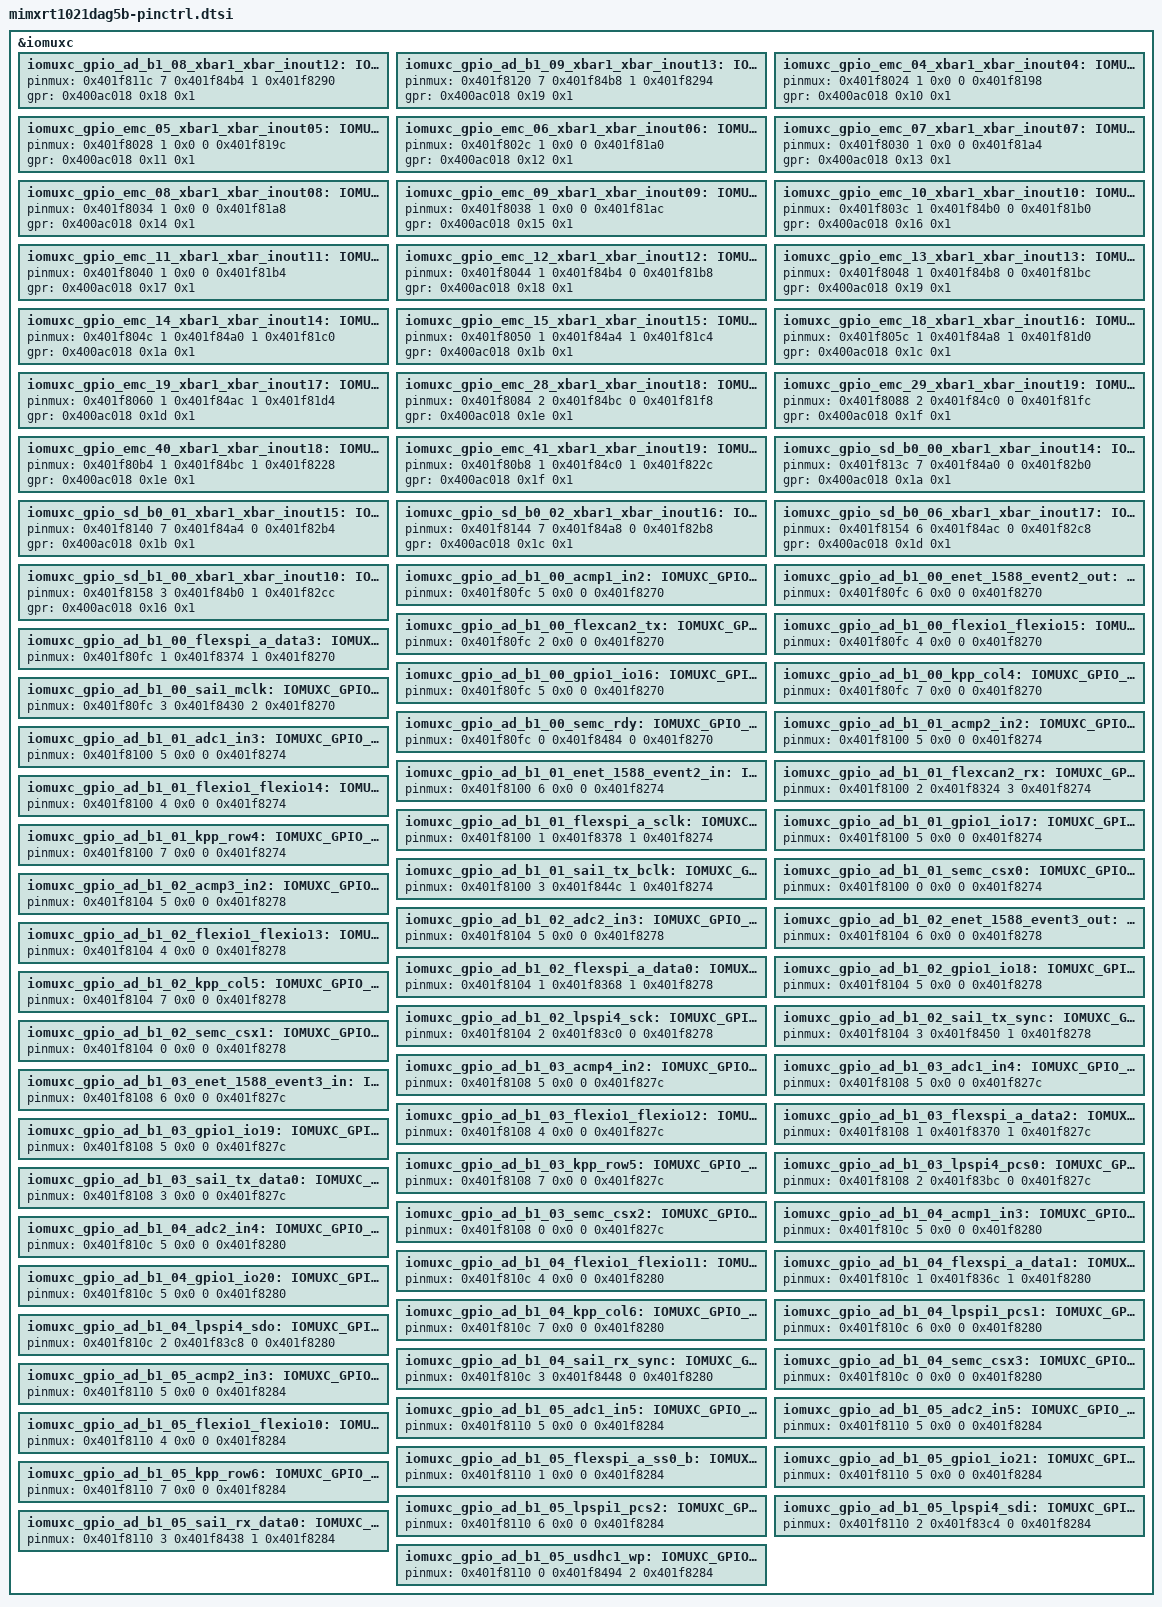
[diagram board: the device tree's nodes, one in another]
/*
 * Copyright 2024, NXP
 * SPDX-License-Identifier: Apache-2.0
 *
 * Note: File generated by gen_soc_headers.py
 * from configuration data for MIMXRT1021DAG5B
 */

/*
 * Delta-deduplicated by dedup_pinctrl.py:
 * based on mimxrt1024dag5a-pinctrl.dtsi with this part's differences applied
 * below (3 removed, 25 changed,
 * 60 added). Regenerate with dedup_pinctrl.py;
 * do not edit by hand.
 * target-hash: 459db1daa55398a1
 */

#include "mimxrt1024dag5a-pinctrl.dtsi"

/delete-node/ &iomuxc_gpio_ad_b0_13_arm_trace1;
/delete-node/ &iomuxc_gpio_ad_b0_14_arm_trace2;
/delete-node/ &iomuxc_gpio_ad_b0_15_arm_trace3;
/delete-node/ &iomuxc_gpio_ad_b1_08_xbar1_xbar_inout12;
/delete-node/ &iomuxc_gpio_ad_b1_09_xbar1_xbar_inout13;
/delete-node/ &iomuxc_gpio_emc_04_xbar1_xbar_inout04;
/delete-node/ &iomuxc_gpio_emc_05_xbar1_xbar_inout05;
/delete-node/ &iomuxc_gpio_emc_06_xbar1_xbar_inout06;
/delete-node/ &iomuxc_gpio_emc_07_xbar1_xbar_inout07;
/delete-node/ &iomuxc_gpio_emc_08_xbar1_xbar_inout08;
/delete-node/ &iomuxc_gpio_emc_09_xbar1_xbar_inout09;
/delete-node/ &iomuxc_gpio_emc_10_xbar1_xbar_inout10;
/delete-node/ &iomuxc_gpio_emc_11_xbar1_xbar_inout11;
/delete-node/ &iomuxc_gpio_emc_12_xbar1_xbar_inout12;
/delete-node/ &iomuxc_gpio_emc_13_xbar1_xbar_inout13;
/delete-node/ &iomuxc_gpio_emc_14_xbar1_xbar_inout14;
/delete-node/ &iomuxc_gpio_emc_15_xbar1_xbar_inout15;
/delete-node/ &iomuxc_gpio_emc_18_xbar1_xbar_inout16;
/delete-node/ &iomuxc_gpio_emc_19_xbar1_xbar_inout17;
/delete-node/ &iomuxc_gpio_emc_28_xbar1_xbar_inout18;
/delete-node/ &iomuxc_gpio_emc_29_xbar1_xbar_inout19;
/delete-node/ &iomuxc_gpio_emc_40_xbar1_xbar_inout18;
/delete-node/ &iomuxc_gpio_emc_41_xbar1_xbar_inout19;
/delete-node/ &iomuxc_gpio_sd_b0_00_xbar1_xbar_inout14;
/delete-node/ &iomuxc_gpio_sd_b0_01_xbar1_xbar_inout15;
/delete-node/ &iomuxc_gpio_sd_b0_02_xbar1_xbar_inout16;
/delete-node/ &iomuxc_gpio_sd_b0_06_xbar1_xbar_inout17;
/delete-node/ &iomuxc_gpio_sd_b1_00_xbar1_xbar_inout10;

&iomuxc {
	/omit-if-no-ref/ iomuxc_gpio_ad_b1_08_xbar1_xbar_inout12: IOMUXC_GPIO_AD_B1_08_XBAR1_XBAR_INOUT12 {
		pinmux = <0x401f811c 7 0x401f84b4 1 0x401f8290>;
		gpr = <0x400ac018 0x18 0x1>;
	};
	/omit-if-no-ref/ iomuxc_gpio_ad_b1_09_xbar1_xbar_inout13: IOMUXC_GPIO_AD_B1_09_XBAR1_XBAR_INOUT13 {
		pinmux = <0x401f8120 7 0x401f84b8 1 0x401f8294>;
		gpr = <0x400ac018 0x19 0x1>;
	};
	/omit-if-no-ref/ iomuxc_gpio_emc_04_xbar1_xbar_inout04: IOMUXC_GPIO_EMC_04_XBAR1_XBAR_INOUT04 {
		pinmux = <0x401f8024 1 0x0 0 0x401f8198>;
		gpr = <0x400ac018 0x10 0x1>;
	};
	/omit-if-no-ref/ iomuxc_gpio_emc_05_xbar1_xbar_inout05: IOMUXC_GPIO_EMC_05_XBAR1_XBAR_INOUT05 {
		pinmux = <0x401f8028 1 0x0 0 0x401f819c>;
		gpr = <0x400ac018 0x11 0x1>;
	};
	/omit-if-no-ref/ iomuxc_gpio_emc_06_xbar1_xbar_inout06: IOMUXC_GPIO_EMC_06_XBAR1_XBAR_INOUT06 {
		pinmux = <0x401f802c 1 0x0 0 0x401f81a0>;
		gpr = <0x400ac018 0x12 0x1>;
	};
	/omit-if-no-ref/ iomuxc_gpio_emc_07_xbar1_xbar_inout07: IOMUXC_GPIO_EMC_07_XBAR1_XBAR_INOUT07 {
		pinmux = <0x401f8030 1 0x0 0 0x401f81a4>;
		gpr = <0x400ac018 0x13 0x1>;
	};
	/omit-if-no-ref/ iomuxc_gpio_emc_08_xbar1_xbar_inout08: IOMUXC_GPIO_EMC_08_XBAR1_XBAR_INOUT08 {
		pinmux = <0x401f8034 1 0x0 0 0x401f81a8>;
		gpr = <0x400ac018 0x14 0x1>;
	};
	/omit-if-no-ref/ iomuxc_gpio_emc_09_xbar1_xbar_inout09: IOMUXC_GPIO_EMC_09_XBAR1_XBAR_INOUT09 {
		pinmux = <0x401f8038 1 0x0 0 0x401f81ac>;
		gpr = <0x400ac018 0x15 0x1>;
	};
	/omit-if-no-ref/ iomuxc_gpio_emc_10_xbar1_xbar_inout10: IOMUXC_GPIO_EMC_10_XBAR1_XBAR_INOUT10 {
		pinmux = <0x401f803c 1 0x401f84b0 0 0x401f81b0>;
		gpr = <0x400ac018 0x16 0x1>;
	};
	/omit-if-no-ref/ iomuxc_gpio_emc_11_xbar1_xbar_inout11: IOMUXC_GPIO_EMC_11_XBAR1_XBAR_INOUT11 {
		pinmux = <0x401f8040 1 0x0 0 0x401f81b4>;
		gpr = <0x400ac018 0x17 0x1>;
	};
	/omit-if-no-ref/ iomuxc_gpio_emc_12_xbar1_xbar_inout12: IOMUXC_GPIO_EMC_12_XBAR1_XBAR_INOUT12 {
		pinmux = <0x401f8044 1 0x401f84b4 0 0x401f81b8>;
		gpr = <0x400ac018 0x18 0x1>;
	};
	/omit-if-no-ref/ iomuxc_gpio_emc_13_xbar1_xbar_inout13: IOMUXC_GPIO_EMC_13_XBAR1_XBAR_INOUT13 {
		pinmux = <0x401f8048 1 0x401f84b8 0 0x401f81bc>;
		gpr = <0x400ac018 0x19 0x1>;
	};
	/omit-if-no-ref/ iomuxc_gpio_emc_14_xbar1_xbar_inout14: IOMUXC_GPIO_EMC_14_XBAR1_XBAR_INOUT14 {
		pinmux = <0x401f804c 1 0x401f84a0 1 0x401f81c0>;
		gpr = <0x400ac018 0x1a 0x1>;
	};
	/omit-if-no-ref/ iomuxc_gpio_emc_15_xbar1_xbar_inout15: IOMUXC_GPIO_EMC_15_XBAR1_XBAR_INOUT15 {
		pinmux = <0x401f8050 1 0x401f84a4 1 0x401f81c4>;
		gpr = <0x400ac018 0x1b 0x1>;
	};
	/omit-if-no-ref/ iomuxc_gpio_emc_18_xbar1_xbar_inout16: IOMUXC_GPIO_EMC_18_XBAR1_XBAR_INOUT16 {
		pinmux = <0x401f805c 1 0x401f84a8 1 0x401f81d0>;
		gpr = <0x400ac018 0x1c 0x1>;
	};
	/omit-if-no-ref/ iomuxc_gpio_emc_19_xbar1_xbar_inout17: IOMUXC_GPIO_EMC_19_XBAR1_XBAR_INOUT17 {
		pinmux = <0x401f8060 1 0x401f84ac 1 0x401f81d4>;
		gpr = <0x400ac018 0x1d 0x1>;
	};
	/omit-if-no-ref/ iomuxc_gpio_emc_28_xbar1_xbar_inout18: IOMUXC_GPIO_EMC_28_XBAR1_XBAR_INOUT18 {
		pinmux = <0x401f8084 2 0x401f84bc 0 0x401f81f8>;
		gpr = <0x400ac018 0x1e 0x1>;
	};
	/omit-if-no-ref/ iomuxc_gpio_emc_29_xbar1_xbar_inout19: IOMUXC_GPIO_EMC_29_XBAR1_XBAR_INOUT19 {
		pinmux = <0x401f8088 2 0x401f84c0 0 0x401f81fc>;
		gpr = <0x400ac018 0x1f 0x1>;
	};
	/omit-if-no-ref/ iomuxc_gpio_emc_40_xbar1_xbar_inout18: IOMUXC_GPIO_EMC_40_XBAR1_XBAR_INOUT18 {
		pinmux = <0x401f80b4 1 0x401f84bc 1 0x401f8228>;
		gpr = <0x400ac018 0x1e 0x1>;
	};
	/omit-if-no-ref/ iomuxc_gpio_emc_41_xbar1_xbar_inout19: IOMUXC_GPIO_EMC_41_XBAR1_XBAR_INOUT19 {
		pinmux = <0x401f80b8 1 0x401f84c0 1 0x401f822c>;
		gpr = <0x400ac018 0x1f 0x1>;
	};
	/omit-if-no-ref/ iomuxc_gpio_sd_b0_00_xbar1_xbar_inout14: IOMUXC_GPIO_SD_B0_00_XBAR1_XBAR_INOUT14 {
		pinmux = <0x401f813c 7 0x401f84a0 0 0x401f82b0>;
		gpr = <0x400ac018 0x1a 0x1>;
	};
	/omit-if-no-ref/ iomuxc_gpio_sd_b0_01_xbar1_xbar_inout15: IOMUXC_GPIO_SD_B0_01_XBAR1_XBAR_INOUT15 {
		pinmux = <0x401f8140 7 0x401f84a4 0 0x401f82b4>;
		gpr = <0x400ac018 0x1b 0x1>;
	};
	/omit-if-no-ref/ iomuxc_gpio_sd_b0_02_xbar1_xbar_inout16: IOMUXC_GPIO_SD_B0_02_XBAR1_XBAR_INOUT16 {
		pinmux = <0x401f8144 7 0x401f84a8 0 0x401f82b8>;
		gpr = <0x400ac018 0x1c 0x1>;
	};
	/omit-if-no-ref/ iomuxc_gpio_sd_b0_06_xbar1_xbar_inout17: IOMUXC_GPIO_SD_B0_06_XBAR1_XBAR_INOUT17 {
		pinmux = <0x401f8154 6 0x401f84ac 0 0x401f82c8>;
		gpr = <0x400ac018 0x1d 0x1>;
	};
	/omit-if-no-ref/ iomuxc_gpio_sd_b1_00_xbar1_xbar_inout10: IOMUXC_GPIO_SD_B1_00_XBAR1_XBAR_INOUT10 {
		pinmux = <0x401f8158 3 0x401f84b0 1 0x401f82cc>;
		gpr = <0x400ac018 0x16 0x1>;
	};
	/omit-if-no-ref/ iomuxc_gpio_ad_b1_00_acmp1_in2: IOMUXC_GPIO_AD_B1_00_ACMP1_IN2 {
		pinmux = <0x401f80fc 5 0x0 0 0x401f8270>;
	};
	/omit-if-no-ref/ iomuxc_gpio_ad_b1_00_enet_1588_event2_out: IOMUXC_GPIO_AD_B1_00_ENET_1588_EVENT2_OUT {
		pinmux = <0x401f80fc 6 0x0 0 0x401f8270>;
	};
	/omit-if-no-ref/ iomuxc_gpio_ad_b1_00_flexcan2_tx: IOMUXC_GPIO_AD_B1_00_FLEXCAN2_TX {
		pinmux = <0x401f80fc 2 0x0 0 0x401f8270>;
	};
	/omit-if-no-ref/ iomuxc_gpio_ad_b1_00_flexio1_flexio15: IOMUXC_GPIO_AD_B1_00_FLEXIO1_FLEXIO15 {
		pinmux = <0x401f80fc 4 0x0 0 0x401f8270>;
	};
	/omit-if-no-ref/ iomuxc_gpio_ad_b1_00_flexspi_a_data3: IOMUXC_GPIO_AD_B1_00_FLEXSPI_A_DATA3 {
		pinmux = <0x401f80fc 1 0x401f8374 1 0x401f8270>;
	};
	/omit-if-no-ref/ iomuxc_gpio_ad_b1_00_gpio1_io16: IOMUXC_GPIO_AD_B1_00_GPIO1_IO16 {
		pinmux = <0x401f80fc 5 0x0 0 0x401f8270>;
	};
	/omit-if-no-ref/ iomuxc_gpio_ad_b1_00_kpp_col4: IOMUXC_GPIO_AD_B1_00_KPP_COL4 {
		pinmux = <0x401f80fc 7 0x0 0 0x401f8270>;
	};
	/omit-if-no-ref/ iomuxc_gpio_ad_b1_00_sai1_mclk: IOMUXC_GPIO_AD_B1_00_SAI1_MCLK {
		pinmux = <0x401f80fc 3 0x401f8430 2 0x401f8270>;
	};
	/omit-if-no-ref/ iomuxc_gpio_ad_b1_00_semc_rdy: IOMUXC_GPIO_AD_B1_00_SEMC_RDY {
		pinmux = <0x401f80fc 0 0x401f8484 0 0x401f8270>;
	};
	/omit-if-no-ref/ iomuxc_gpio_ad_b1_01_acmp2_in2: IOMUXC_GPIO_AD_B1_01_ACMP2_IN2 {
		pinmux = <0x401f8100 5 0x0 0 0x401f8274>;
	};
	/omit-if-no-ref/ iomuxc_gpio_ad_b1_01_adc1_in3: IOMUXC_GPIO_AD_B1_01_ADC1_IN3 {
		pinmux = <0x401f8100 5 0x0 0 0x401f8274>;
	};
	/omit-if-no-ref/ iomuxc_gpio_ad_b1_01_enet_1588_event2_in: IOMUXC_GPIO_AD_B1_01_ENET_1588_EVENT2_IN {
		pinmux = <0x401f8100 6 0x0 0 0x401f8274>;
	};
	/omit-if-no-ref/ iomuxc_gpio_ad_b1_01_flexcan2_rx: IOMUXC_GPIO_AD_B1_01_FLEXCAN2_RX {
		pinmux = <0x401f8100 2 0x401f8324 3 0x401f8274>;
	};
	/omit-if-no-ref/ iomuxc_gpio_ad_b1_01_flexio1_flexio14: IOMUXC_GPIO_AD_B1_01_FLEXIO1_FLEXIO14 {
		pinmux = <0x401f8100 4 0x0 0 0x401f8274>;
	};
	/omit-if-no-ref/ iomuxc_gpio_ad_b1_01_flexspi_a_sclk: IOMUXC_GPIO_AD_B1_01_FLEXSPI_A_SCLK {
		pinmux = <0x401f8100 1 0x401f8378 1 0x401f8274>;
	};
	/omit-if-no-ref/ iomuxc_gpio_ad_b1_01_gpio1_io17: IOMUXC_GPIO_AD_B1_01_GPIO1_IO17 {
		pinmux = <0x401f8100 5 0x0 0 0x401f8274>;
	};
	/omit-if-no-ref/ iomuxc_gpio_ad_b1_01_kpp_row4: IOMUXC_GPIO_AD_B1_01_KPP_ROW4 {
		pinmux = <0x401f8100 7 0x0 0 0x401f8274>;
	};
	/omit-if-no-ref/ iomuxc_gpio_ad_b1_01_sai1_tx_bclk: IOMUXC_GPIO_AD_B1_01_SAI1_TX_BCLK {
		pinmux = <0x401f8100 3 0x401f844c 1 0x401f8274>;
	};
	/omit-if-no-ref/ iomuxc_gpio_ad_b1_01_semc_csx0: IOMUXC_GPIO_AD_B1_01_SEMC_CSX0 {
		pinmux = <0x401f8100 0 0x0 0 0x401f8274>;
	};
	/omit-if-no-ref/ iomuxc_gpio_ad_b1_02_acmp3_in2: IOMUXC_GPIO_AD_B1_02_ACMP3_IN2 {
		pinmux = <0x401f8104 5 0x0 0 0x401f8278>;
	};
	/omit-if-no-ref/ iomuxc_gpio_ad_b1_02_adc2_in3: IOMUXC_GPIO_AD_B1_02_ADC2_IN3 {
		pinmux = <0x401f8104 5 0x0 0 0x401f8278>;
	};
	/omit-if-no-ref/ iomuxc_gpio_ad_b1_02_enet_1588_event3_out: IOMUXC_GPIO_AD_B1_02_ENET_1588_EVENT3_OUT {
		pinmux = <0x401f8104 6 0x0 0 0x401f8278>;
	};
	/omit-if-no-ref/ iomuxc_gpio_ad_b1_02_flexio1_flexio13: IOMUXC_GPIO_AD_B1_02_FLEXIO1_FLEXIO13 {
		pinmux = <0x401f8104 4 0x0 0 0x401f8278>;
	};
	/omit-if-no-ref/ iomuxc_gpio_ad_b1_02_flexspi_a_data0: IOMUXC_GPIO_AD_B1_02_FLEXSPI_A_DATA0 {
		pinmux = <0x401f8104 1 0x401f8368 1 0x401f8278>;
	};
	/omit-if-no-ref/ iomuxc_gpio_ad_b1_02_gpio1_io18: IOMUXC_GPIO_AD_B1_02_GPIO1_IO18 {
		pinmux = <0x401f8104 5 0x0 0 0x401f8278>;
	};
	/omit-if-no-ref/ iomuxc_gpio_ad_b1_02_kpp_col5: IOMUXC_GPIO_AD_B1_02_KPP_COL5 {
		pinmux = <0x401f8104 7 0x0 0 0x401f8278>;
	};
	/omit-if-no-ref/ iomuxc_gpio_ad_b1_02_lpspi4_sck: IOMUXC_GPIO_AD_B1_02_LPSPI4_SCK {
		pinmux = <0x401f8104 2 0x401f83c0 0 0x401f8278>;
	};
	/omit-if-no-ref/ iomuxc_gpio_ad_b1_02_sai1_tx_sync: IOMUXC_GPIO_AD_B1_02_SAI1_TX_SYNC {
		pinmux = <0x401f8104 3 0x401f8450 1 0x401f8278>;
	};
	/omit-if-no-ref/ iomuxc_gpio_ad_b1_02_semc_csx1: IOMUXC_GPIO_AD_B1_02_SEMC_CSX1 {
		pinmux = <0x401f8104 0 0x0 0 0x401f8278>;
	};
	/omit-if-no-ref/ iomuxc_gpio_ad_b1_03_acmp4_in2: IOMUXC_GPIO_AD_B1_03_ACMP4_IN2 {
		pinmux = <0x401f8108 5 0x0 0 0x401f827c>;
	};
	/omit-if-no-ref/ iomuxc_gpio_ad_b1_03_adc1_in4: IOMUXC_GPIO_AD_B1_03_ADC1_IN4 {
		pinmux = <0x401f8108 5 0x0 0 0x401f827c>;
	};
	/omit-if-no-ref/ iomuxc_gpio_ad_b1_03_enet_1588_event3_in: IOMUXC_GPIO_AD_B1_03_ENET_1588_EVENT3_IN {
		pinmux = <0x401f8108 6 0x0 0 0x401f827c>;
	};
	/omit-if-no-ref/ iomuxc_gpio_ad_b1_03_flexio1_flexio12: IOMUXC_GPIO_AD_B1_03_FLEXIO1_FLEXIO12 {
		pinmux = <0x401f8108 4 0x0 0 0x401f827c>;
	};
	/omit-if-no-ref/ iomuxc_gpio_ad_b1_03_flexspi_a_data2: IOMUXC_GPIO_AD_B1_03_FLEXSPI_A_DATA2 {
		pinmux = <0x401f8108 1 0x401f8370 1 0x401f827c>;
	};
	/omit-if-no-ref/ iomuxc_gpio_ad_b1_03_gpio1_io19: IOMUXC_GPIO_AD_B1_03_GPIO1_IO19 {
		pinmux = <0x401f8108 5 0x0 0 0x401f827c>;
	};
	/omit-if-no-ref/ iomuxc_gpio_ad_b1_03_kpp_row5: IOMUXC_GPIO_AD_B1_03_KPP_ROW5 {
		pinmux = <0x401f8108 7 0x0 0 0x401f827c>;
	};
	/omit-if-no-ref/ iomuxc_gpio_ad_b1_03_lpspi4_pcs0: IOMUXC_GPIO_AD_B1_03_LPSPI4_PCS0 {
		pinmux = <0x401f8108 2 0x401f83bc 0 0x401f827c>;
	};
	/omit-if-no-ref/ iomuxc_gpio_ad_b1_03_sai1_tx_data0: IOMUXC_GPIO_AD_B1_03_SAI1_TX_DATA0 {
		pinmux = <0x401f8108 3 0x0 0 0x401f827c>;
	};
	/omit-if-no-ref/ iomuxc_gpio_ad_b1_03_semc_csx2: IOMUXC_GPIO_AD_B1_03_SEMC_CSX2 {
		pinmux = <0x401f8108 0 0x0 0 0x401f827c>;
	};
	/omit-if-no-ref/ iomuxc_gpio_ad_b1_04_acmp1_in3: IOMUXC_GPIO_AD_B1_04_ACMP1_IN3 {
		pinmux = <0x401f810c 5 0x0 0 0x401f8280>;
	};
	/omit-if-no-ref/ iomuxc_gpio_ad_b1_04_adc2_in4: IOMUXC_GPIO_AD_B1_04_ADC2_IN4 {
		pinmux = <0x401f810c 5 0x0 0 0x401f8280>;
	};
	/omit-if-no-ref/ iomuxc_gpio_ad_b1_04_flexio1_flexio11: IOMUXC_GPIO_AD_B1_04_FLEXIO1_FLEXIO11 {
		pinmux = <0x401f810c 4 0x0 0 0x401f8280>;
	};
	/omit-if-no-ref/ iomuxc_gpio_ad_b1_04_flexspi_a_data1: IOMUXC_GPIO_AD_B1_04_FLEXSPI_A_DATA1 {
		pinmux = <0x401f810c 1 0x401f836c 1 0x401f8280>;
	};
	/omit-if-no-ref/ iomuxc_gpio_ad_b1_04_gpio1_io20: IOMUXC_GPIO_AD_B1_04_GPIO1_IO20 {
		pinmux = <0x401f810c 5 0x0 0 0x401f8280>;
	};
	/omit-if-no-ref/ iomuxc_gpio_ad_b1_04_kpp_col6: IOMUXC_GPIO_AD_B1_04_KPP_COL6 {
		pinmux = <0x401f810c 7 0x0 0 0x401f8280>;
	};
	/omit-if-no-ref/ iomuxc_gpio_ad_b1_04_lpspi1_pcs1: IOMUXC_GPIO_AD_B1_04_LPSPI1_PCS1 {
		pinmux = <0x401f810c 6 0x0 0 0x401f8280>;
	};
	/omit-if-no-ref/ iomuxc_gpio_ad_b1_04_lpspi4_sdo: IOMUXC_GPIO_AD_B1_04_LPSPI4_SDO {
		pinmux = <0x401f810c 2 0x401f83c8 0 0x401f8280>;
	};
	/omit-if-no-ref/ iomuxc_gpio_ad_b1_04_sai1_rx_sync: IOMUXC_GPIO_AD_B1_04_SAI1_RX_SYNC {
		pinmux = <0x401f810c 3 0x401f8448 0 0x401f8280>;
	};
	/omit-if-no-ref/ iomuxc_gpio_ad_b1_04_semc_csx3: IOMUXC_GPIO_AD_B1_04_SEMC_CSX3 {
		pinmux = <0x401f810c 0 0x0 0 0x401f8280>;
	};
	/omit-if-no-ref/ iomuxc_gpio_ad_b1_05_acmp2_in3: IOMUXC_GPIO_AD_B1_05_ACMP2_IN3 {
		pinmux = <0x401f8110 5 0x0 0 0x401f8284>;
	};
	/omit-if-no-ref/ iomuxc_gpio_ad_b1_05_adc1_in5: IOMUXC_GPIO_AD_B1_05_ADC1_IN5 {
		pinmux = <0x401f8110 5 0x0 0 0x401f8284>;
	};
	/omit-if-no-ref/ iomuxc_gpio_ad_b1_05_adc2_in5: IOMUXC_GPIO_AD_B1_05_ADC2_IN5 {
		pinmux = <0x401f8110 5 0x0 0 0x401f8284>;
	};
	/omit-if-no-ref/ iomuxc_gpio_ad_b1_05_flexio1_flexio10: IOMUXC_GPIO_AD_B1_05_FLEXIO1_FLEXIO10 {
		pinmux = <0x401f8110 4 0x0 0 0x401f8284>;
	};
	/omit-if-no-ref/ iomuxc_gpio_ad_b1_05_flexspi_a_ss0_b: IOMUXC_GPIO_AD_B1_05_FLEXSPI_A_SS0_B {
		pinmux = <0x401f8110 1 0x0 0 0x401f8284>;
	};
	/omit-if-no-ref/ iomuxc_gpio_ad_b1_05_gpio1_io21: IOMUXC_GPIO_AD_B1_05_GPIO1_IO21 {
		pinmux = <0x401f8110 5 0x0 0 0x401f8284>;
	};
	/omit-if-no-ref/ iomuxc_gpio_ad_b1_05_kpp_row6: IOMUXC_GPIO_AD_B1_05_KPP_ROW6 {
		pinmux = <0x401f8110 7 0x0 0 0x401f8284>;
	};
	/omit-if-no-ref/ iomuxc_gpio_ad_b1_05_lpspi1_pcs2: IOMUXC_GPIO_AD_B1_05_LPSPI1_PCS2 {
		pinmux = <0x401f8110 6 0x0 0 0x401f8284>;
	};
	/omit-if-no-ref/ iomuxc_gpio_ad_b1_05_lpspi4_sdi: IOMUXC_GPIO_AD_B1_05_LPSPI4_SDI {
		pinmux = <0x401f8110 2 0x401f83c4 0 0x401f8284>;
	};
	/omit-if-no-ref/ iomuxc_gpio_ad_b1_05_sai1_rx_data0: IOMUXC_GPIO_AD_B1_05_SAI1_RX_DATA0 {
		pinmux = <0x401f8110 3 0x401f8438 1 0x401f8284>;
	};
	/omit-if-no-ref/ iomuxc_gpio_ad_b1_05_usdhc1_wp: IOMUXC_GPIO_AD_B1_05_USDHC1_WP {
		pinmux = <0x401f8110 0 0x401f8494 2 0x401f8284>;
	};
};
